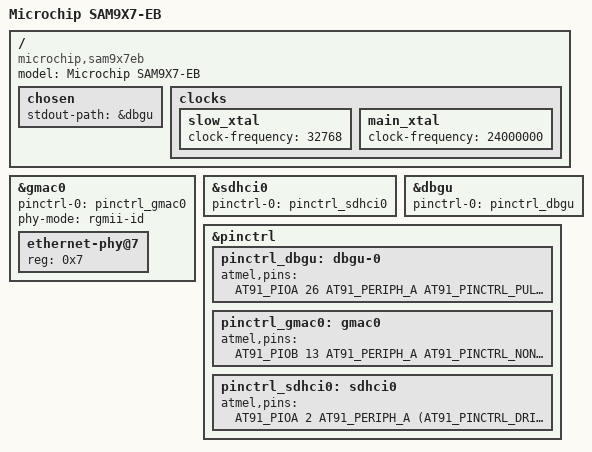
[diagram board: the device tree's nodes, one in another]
// SPDX-License-Identifier: (GPL-2.0+ OR MIT)
/*
 * sam9x7.dts - Device Tree file for SAM9X7 EK board
 *
 * Copyright (C) 2021 Microchip Technology Inc. and its subsidiaries
 *
 * Author: Balamanikandan Gunasundar <balamanikandan.gunasundar@microchip.com>
 * 	   Varshini Rajendran <varshini.rajendran@microchip.com>
 */
/dts-v1/;
#include "sam9x7.dtsi"

/ {
	model = "Microchip SAM9X7-EB";
	compatible = "microchip,sam9x7eb", "microchip,sam9x7", "atmel,at91sam9";

	chosen {
		stdout-path = &dbgu;
	};

	clocks {
		slow_xtal: slow_xtal {
			clock-frequency = <32768>;
		};

		main_xtal: main_xtal {
			clock-frequency = <24000000>;
		};
	};
};

&gmac0 {
	#address-cells = <1>;
	#size-cells = <0>;
	pinctrl-names = "default";
	pinctrl-0 = <&pinctrl_gmac0>;
	phy-mode = "rgmii-id";
	status = "okay";

	ethernet-phy@7 {
		reg = <0x7>;
	};
};

&sdhci0 {
	pinctrl-names = "default";
	pinctrl-0 = <&pinctrl_sdhci0>;
	status = "okay";
};

&dbgu {
	pinctrl-names = "default";
	pinctrl-0 = <&pinctrl_dbgu>;
};

&pinctrl {
	pinctrl_dbgu: dbgu-0 {
		atmel,pins =
			<AT91_PIOA 26 AT91_PERIPH_A AT91_PINCTRL_PULL_UP
			 AT91_PIOA 27 AT91_PERIPH_A AT91_PINCTRL_NONE>;
	};

	pinctrl_gmac0: gmac0 {
		atmel,pins =
			<AT91_PIOB 13 AT91_PERIPH_A 	AT91_PINCTRL_NONE	/* ETH_TX0   */
			 AT91_PIOB 14 AT91_PERIPH_A 	AT91_PINCTRL_NONE	/* ETH_TX1   */
			 AT91_PIOB 4  AT91_PERIPH_A 	AT91_PINCTRL_NONE	/* ETH_TX2   */
			 AT91_PIOB 5  AT91_PERIPH_A 	AT91_PINCTRL_NONE	/* ETH_TX3   */
			 AT91_PIOB 7  AT91_PERIPH_A 	AT91_PINCTRL_NONE	/* ETH_TXCTL */
			 AT91_PIOB 6  AT91_PERIPH_A 	AT91_PINCTRL_PULL_UP	/* ETH_TXCK  */

			 AT91_PIOB 11 AT91_PERIPH_A 	AT91_PINCTRL_NONE	/* ETH_RX0   */
			 AT91_PIOB 12 AT91_PERIPH_A 	AT91_PINCTRL_NONE	/* ETH_RX1   */
			 AT91_PIOB 0  AT91_PERIPH_A	AT91_PINCTRL_NONE	/* ETH_RX2   */
			 AT91_PIOB 1  AT91_PERIPH_A 	AT91_PINCTRL_NONE	/* ETH_RX3   */
			 AT91_PIOB 8  AT91_PERIPH_A 	AT91_PINCTRL_NONE	/* ETH_RXCK  */
			 AT91_PIOB 3  AT91_PERIPH_A 	AT91_PINCTRL_NONE	/* ETH_RXCTL */

			 AT91_PIOB 10 AT91_PERIPH_A 	AT91_PINCTRL_NONE	/* ETH_MDC   */
			 AT91_PIOB 9  AT91_PERIPH_A 	AT91_PINCTRL_NONE	/* ETH_MDIO  */

			 AT91_PIOB 2  AT91_PERIPH_A 	AT91_PINCTRL_NONE	/* ETH_125CK */
			 AT91_PIOC 25 AT91_PERIPH_C 	AT91_PINCTRL_NONE	/* NRST_OUT  */
			 AT91_PIOD 5  AT91_PERIPH_A 	AT91_PINCTRL_NONE>;	/* ETH_INT   */
	};

	pinctrl_sdhci0: sdhci0 {
		atmel,pins =
			<AT91_PIOA 2 AT91_PERIPH_A
			 (AT91_PINCTRL_DRIVE_STRENGTH_HI | AT91_PINCTRL_SLEWRATE_ENA)				/* PA2 CK  periph A with pullup */
			 AT91_PIOA 1 AT91_PERIPH_A
			 (AT91_PINCTRL_PULL_UP | AT91_PINCTRL_DRIVE_STRENGTH_HI | AT91_PINCTRL_SLEWRATE_ENA)	/* PA1 CMD periph A with pullup */
			 AT91_PIOA 0 AT91_PERIPH_A
			 (AT91_PINCTRL_PULL_UP | AT91_PINCTRL_DRIVE_STRENGTH_HI | AT91_PINCTRL_SLEWRATE_ENA)	/* PA0 DAT0 periph A */
			 AT91_PIOA 3 AT91_PERIPH_A
			 (AT91_PINCTRL_PULL_UP | AT91_PINCTRL_DRIVE_STRENGTH_HI | AT91_PINCTRL_SLEWRATE_ENA)	/* PA3 DAT1 periph A with pullup */
			 AT91_PIOA 4 AT91_PERIPH_A
			 (AT91_PINCTRL_PULL_UP | AT91_PINCTRL_DRIVE_STRENGTH_HI | AT91_PINCTRL_SLEWRATE_ENA)	/* PA4 DAT2 periph A with pullup */
			 AT91_PIOA 5 AT91_PERIPH_A
			 (AT91_PINCTRL_PULL_UP | AT91_PINCTRL_DRIVE_STRENGTH_HI | AT91_PINCTRL_SLEWRATE_ENA)>;	/* PA5 DAT3 periph A with pullup */
	};
};
